# M55M1 register map
File version: 1.0
Registers are 32-bit, read-write, reset 0x0 unless marked. A register's access mark holds for its fields unless they carry their own. Offsets are from the block's base; [hi:lo] are bit positions; {n}, {i} and the like mark numbered series.

## DPM_NS — SCU Register Map
Base 0x50402600
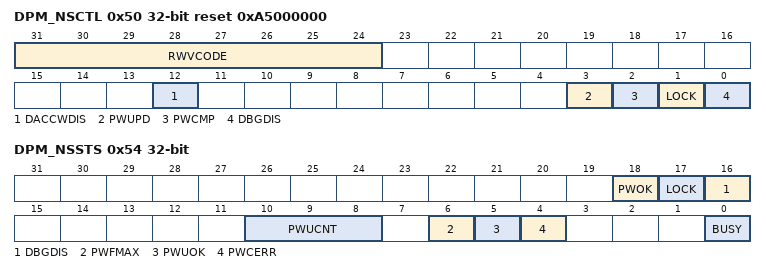
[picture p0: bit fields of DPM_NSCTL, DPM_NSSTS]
0x50 DPM_NSCTL reset 0xA5000000 (reset mask 0xFFFFFFF0) — Non-secure DPM Control Register
  [31:24] RWVCODE — Write Verify Code and Read Verify Code. Read operation:
    90=The write verify code, 0x5A, is needed to do a valid write to DPM_NSCTL; 165=The read access for DPM_NSCTL is correct
  [12] DACCWDIS — Debug Write Access Disable Bit. This bit disables the ability of external debugger to set Non-secure DPM registers for debug authentication.
    0=External debugger can set Non-secure DPM registers; 1=External debugger cannot set Non-secure DPM registers
  [3] PWUPD — Non-secure DPM Password Update Bit. Set to enter the process of updating Non-secure DPM password. Note 1: This bit should be set with PWCMP equal to 0. Note 2: This bit will be cleared after the update process is finished.
    0=No operation; 1=Update Non-secure DPM password
  [2] PWCMP — Non-secure DPM Password Compare Bit. Set to enter the process of compare Non-secure DPM password. Note: This bit will be cleared after the comparison process is finished.
    0=No operation; 1=Compare Non-secure DPM password
  [1] LOCK — Set Non-secure DPM Debug Lock Bit. When this bit is read as 0, it can be written to 1 to configure the Non-secure DPM LOCK bit (LOCKNS). When written: Note: This bit can be set to 1 but cannot be cleared to 0.
    0=No operation; 1=Trigger the process to set LOCKNS configuration bit
  [0] DBGDIS — Set Non-secure DPM Debug Disable Bit. When this bit is read as 0, it can be written to 1 to configure the Non-secure DPM DBGDIS bit (DBGDISNS). When written: Note: This bit can be set to 1 but cannot be cleared to 0.
    0=No operation; 1=Trigger the process to set DBGDISNS configuration bit
0x54 DPM_NSSTS (reset mask 0xFFF0F0FF) — Non-secure DPM Status Register
  [18] PWOK ro — Non-secure Password OK Flag (Read Only). This bit indicates the Non-secure DPM password has been checked and is correct.
    0=The Non-secure DPM password has not been checked pass, yet; 1=The Non-secure DPM password has been checked pass since last cold reset
  [17] LOCK ro — Non-secure Debug Lock Flag (Read Only). This bit indicates the current value of LOCKNS bit.
  [16] DBGDIS ro — Non-secure Debug Disable Flag (Read Only). This bit indicates the current value of DBGDISNS bit. {PWOK, LOCK, DBGDIS} bits define the current state of DPM.
    0=DEFAULT state. LOCKED state; 1=CLOSE state; 5=OPEN state
  [10:8] PWUCNT ro — Non-secure DPM Password Updated Times (Read Only). This bit indicates how many times of non-secure password has been updated. The max value is 7. If PWUCNT reached the max value, Non-secure DPM password cannot be updated anymore.
  [6] PWFMAX ro — Non-secure DPM Password Fail Times Maximum Reached Flag (Read Only). This bit indicates if the fail times of comparing Non-secure DPM password reached max times.
    0=Max time has not reached and Non-secure DPM password comparison can be triggered; 1=Max time reached and Non-secure DPM password comparison cannot be processed anymore
  [5] PWUOK — Non-secure DPM Password Updated Flag. This bit indicates Non-secure DPM password has been updated correctly. When read: Note: This flag is write-one-clear.
    0=No successful updating process has happened; 1=There is at least one successful updating process since last clearing of this bit
  [4] PWCERR — Non-secure DPM Password Compared Error Flag. This bit indicates the result of Non-secure DPM password comparison. Note: This flag is write-one-clear.
    0=The result of Non-secure DPM password is correct; 1=The result of Non-secure DPM password is incorrect
  [0] BUSY ro — DPM Busy Flag (Read Only). This bit indicates the DPM is busy.
    0=DPM is not busy and writing to any register is accepted; 1=DPM is busy and other bits in DPM_NSSTS register are not valid and writing to any register is ignored
{0x60+4i} DPM_NSPW{i} wo reset 0xFFFFFFFF (i=0..3) — Non-secure DPM Password {i}
  [31:0] PW — Password. Write password[{32i+31}:{32i}] to this register to update or compare Non-secure DPM password. It is write-only and always read as 0xFFFFFFFF.
